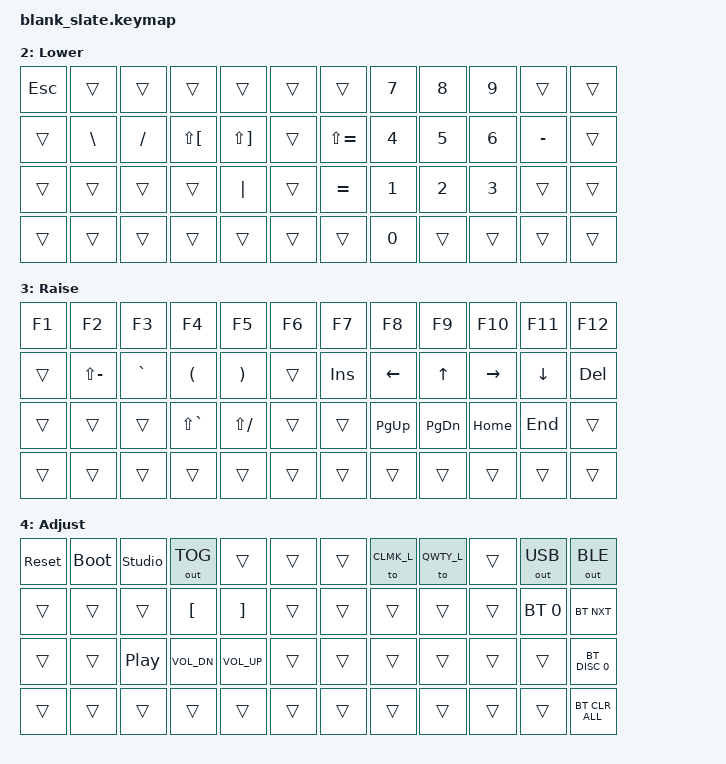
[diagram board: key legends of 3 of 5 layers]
/*
 * Copyright (c) 2022 Pete Johanson
 *
 * SPDX-License-Identifier: MIT
 */

#include <behaviors.dtsi>
#include <dt-bindings/zmk/keys.h>
#include <dt-bindings/zmk/bt.h>
#include <dt-bindings/zmk/outputs.h>

// Swap CLMK_L/QWTY_L values (and their layer block order) to change the default layout.
#define QWTY_L 0
#define CLMK_L 1
#define LOWR_L 2
#define UPPR_L 3
#define AJST_L 4

&lt { quick_tap_ms = <200>; };

#define BT(n) BT_SEL n

// Fixed thumb row shared by all alpha layers.
#define THUMB_ROW \
    &kp LCTRL  &kp PG_UP  &kp LALT  &kp LGUI  &mo LOWR_L  &kp SPACE  &mo UPPR_L  &kp RSHFT  &kp RCTRL  &kp RALT  &kp CAPS

/*
 * ALPHA_LAYER — pass 10+10+7 inner alpha keys; modifiers and thumb row are fixed.
 *   row1:  TAB  [r1_0 .. r1_9]                                    ESC
 *   row2: CTRL  [r2_0 .. r2_9]                                   BSPC
 *   row3: SHFT  [r3_0 .. r3_6]  morph_dot  morph_comma  SQT  RET
 *   row4: THUMB_ROW
 */
#define ALPHA_LAYER( \
    r1_0, r1_1, r1_2, r1_3, r1_4,  r1_5, r1_6, r1_7, r1_8, r1_9, \
    r2_0, r2_1, r2_2, r2_3, r2_4,  r2_5, r2_6, r2_7, r2_8, r2_9, \
    r3_0, r3_1, r3_2, r3_3, r3_4,  r3_5, r3_6                     \
) \
    &kp TAB    r1_0 r1_1 r1_2 r1_3 r1_4  r1_5 r1_6 r1_7       r1_8         r1_9    &kp ESC  \
    &kp LCTRL  r2_0 r2_1 r2_2 r2_3 r2_4  r2_5 r2_6 r2_7       r2_8         r2_9    &kp BSPC \
    &kp LSHFT  r3_0 r3_1 r3_2 r3_3 r3_4  r3_5 r3_6 &morph_dot &morph_comma &kp SQT &kp RET \
    THUMB_ROW

/ {
    chosen {
        zmk,physical-layout = &layout_ortho_4x12_1x2u;
    };

    behaviors {
        morph_dot: morph_dot {
            compatible = "zmk,behavior-mod-morph";
            #binding-cells = <0>;
            bindings = <&kp DOT>, <&kp LESS_THAN>;
            mods = <(MOD_LSFT|MOD_RSFT)>;
        };
        morph_comma: morph_comma {
            compatible = "zmk,behavior-mod-morph";
            #binding-cells = <0>;
            bindings = <&kp COMMA>, <&kp GREATER_THAN>;
            mods = <(MOD_LSFT|MOD_RSFT)>;
        };
    };

    cond_layers {
        compatible = "zmk,conditional-layers";
        tri {
            if-layers = <LOWR_L UPPR_L>;
            then-layer = <AJST_L>;
        };
    };

    keymap {
        compatible = "zmk,keymap";

        qwerty_layer {
            display-name = "Qwerty";
            bindings = <ALPHA_LAYER(
                &kp Q,  &kp W,  &kp E,  &kp R,  &kp T,    &kp Y,  &kp U,  &kp I,  &kp O,   &kp P,
                &kp A,  &kp S,  &kp D,  &kp F,  &kp G,    &kp H,  &kp J,  &kp K,  &kp L,   &kp SEMI,
                &kp Z,  &kp X,  &kp C,  &kp V,  &kp B,    &kp N,  &kp M
            )>;
        };

        colemak_layer {
            display-name = "Colemak";
            bindings = <ALPHA_LAYER(
                &kp Q,  &kp W,  &kp F,  &kp P,  &kp G,    &kp J,  &kp L,  &kp U,  &kp Y,   &kp SEMI,
                &kp A,  &kp R,  &kp S,  &kp T,  &kp D,    &kp H,  &kp N,  &kp E,  &kp I,   &kp O,
                &kp Z,  &kp X,  &kp C,  &kp V,  &kp B,    &kp K,  &kp M
            )>;
        };

        lower_layer {
            display-name = "Lower";
            bindings = <
                &kp ESC  &trans    &trans    &trans        &trans        &trans  &trans         &kp N7  &kp N8  &kp N9  &trans     &trans
                &trans   &kp BSLH  &kp FSLH  &kp LS(LBKT)  &kp LS(RBKT)  &trans  &kp LS(EQUAL)  &kp N4  &kp N5  &kp N6  &kp MINUS  &trans
                &trans   &trans    &trans    &trans        &kp PIPE      &trans  &kp EQUAL      &kp N1  &kp N2  &kp N3  &trans     &trans
                &trans   &trans    &trans    &trans        &trans        &trans  &trans         &kp N0  &trans  &trans  &trans     &trans
            >;
        };

        raise_layer {
            display-name = "Raise";
            bindings = <
                &kp F1  &kp F2        &kp F3     &kp F4         &kp F5        &kp F6  &kp F7   &kp F8     &kp F9     &kp F10    &kp F11   &kp F12
                &trans  &kp LS(MINUS) &kp GRAVE  &kp LPAR       &kp RPAR      &trans  &kp INS  &kp LEFT   &kp UP     &kp RIGHT  &kp DOWN  &kp DEL
                &trans  &trans        &trans     &kp LS(GRAVE)  &kp LS(FSLH)  &trans  &trans   &kp PG_UP  &kp PG_DN  &kp HOME   &kp END   &trans
                &trans  &trans        &trans     &trans         &trans        &trans  &trans   &trans     &trans     &trans     &trans    &trans
            >;
        };

        adjust_layer {
            display-name = "Adjust";
            bindings = <
                &sys_reset  &bootloader  &studio_unlock  &out OUT_TOG  &trans        &trans  &trans  &to CLMK_L  &to QWTY_L  &trans  &out OUT_USB   &out OUT_BLE
                &trans      &trans       &trans          &kp LBKT      &kp RBKT      &trans  &trans  &trans      &trans      &trans  &bt BT_SEL 0   &bt BT_NXT
                &trans      &trans       &kp C_PP        &kp C_VOL_DN  &kp C_VOL_UP  &trans  &trans  &trans      &trans      &trans  &trans         &bt BT_DISC 0
                &trans      &trans       &trans          &trans        &trans        &trans  &trans  &trans      &trans      &trans  &trans         &bt BT_CLR_ALL
            >;
        };
    };
};
